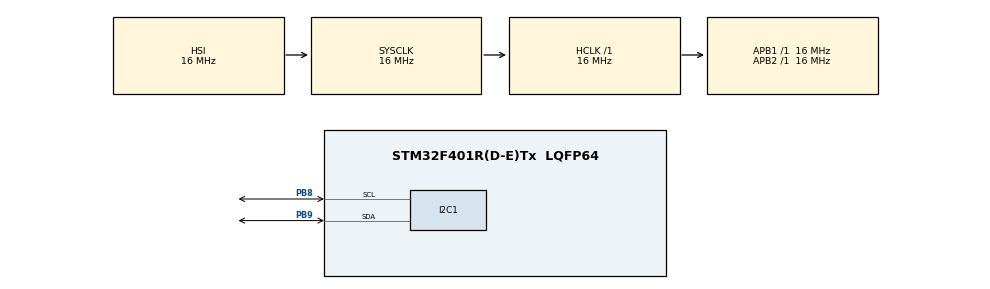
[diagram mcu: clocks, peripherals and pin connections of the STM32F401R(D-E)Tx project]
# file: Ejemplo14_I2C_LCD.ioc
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Mcu.Family=STM32F4
Mcu.Name=STM32F401R(D-E)Tx
Mcu.Package=LQFP64
NVIC.PriorityGroup=NVIC_PRIORITYGROUP_4
PA13.Mode=Serial_Wire
PA13.Signal=SYS_JTMS-SWDIO
PA14.Mode=Serial_Wire
PA14.Signal=SYS_JTCK-SWCLK
PB8.Mode=I2C
PB8.Signal=I2C1_SCL
PB9.Mode=I2C
PB9.Signal=I2C1_SDA
ProjectManager.HeapSize=0x200
ProjectManager.StackSize=0x400
ProjectManager.TargetToolchain=STM32CubeIDE
RCC.AHBFreq_Value=16000000
RCC.APB1Freq_Value=16000000
RCC.APB2Freq_Value=16000000
RCC.CortexFreq_Value=16000000
RCC.HSE_VALUE=25000000
RCC.HSI_VALUE=16000000
RCC.LSE_VALUE=32768
RCC.SYSCLKFreq_VALUE=16000000
RCC.VCOOutputFreq_Value=192000000
board=custom

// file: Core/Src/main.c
/* USER CODE BEGIN Header */
/**
  ******************************************************************************
  * @file           : main.c
  * @brief          : Main program body
  ******************************************************************************
  * @attention
  *
  * Copyright (c) 2023 STMicroelectronics.
  * All rights reserved.
  *
  * This software is licensed under terms that can be found in the LICENSE file
  * in the root directory of this software component.
  * If no LICENSE file comes with this software, it is provided AS-IS.
  *
  ******************************************************************************
  */
/* USER CODE END Header */
#include "main.h"
#include "i2c.h"
#include "gpio.h"

/* USER CODE BEGIN Includes */

#include "LCD.h"
/* USER CODE END Includes */

void SystemClock_Config(void);

int main(void)
{

  /* MCU Configuration--------------------------------------------------------*/

  /* Reset of all peripherals, Initializes the Flash interface and the Systick. */
  HAL_Init();

  /* Configure the system clock */
  SystemClock_Config();

  /* Initialize all configured peripherals */
  MX_GPIO_Init();
  MX_I2C1_Init();
  /* USER CODE BEGIN 2 */
LCD_STM32_INIT();
/*LCD_STM32_SET_CURSOR(0, fila1);
LCD_STM32_PRINT_CHAR('G');
LCD_STM32_PRINT_CHAR('O');
LCD_STM32_PRINT_CHAR('D');
LCD_STM32_PRINT_CHAR('O');
LCD_STM32_SET_CURSOR(0, fila2);
LCD_STM32_PRINT_CHAR('S');
LCD_STM32_PRINT_CHAR('T');
LCD_STM32_PRINT_CHAR('M');
LCD_STM32_PRINT_CHAR('3');
LCD_STM32_PRINT_CHAR('2');*/

LCD_STM32_SET_CURSOR(0, fila1);
LCD_STM32_PRINT_STRING("LCD CON I2C");
uint8_t count  = 0;
char str_count[15];
  /* USER CODE END 2 */

  /* Infinite loop */
  /* USER CODE BEGIN WHILE */
  while (1)
  {
	  for (count = 0; count < 256; ++count) {
		  LCD_STM32_SET_CURSOR(0, fila2);
		  sprintf(str_count,"C:%03u",count);
		  LCD_STM32_PRINT_STRING(str_count);
		  HAL_Delay(300);
	  }
    /* USER CODE END WHILE */

  }
}

void SystemClock_Config(void)
{
  RCC_OscInitTypeDef RCC_OscInitStruct = {0};
  RCC_ClkInitTypeDef RCC_ClkInitStruct = {0};

  /** Configure the main internal regulator output voltage
  */
  __HAL_RCC_PWR_CLK_ENABLE();
  __HAL_PWR_VOLTAGESCALING_CONFIG(PWR_REGULATOR_VOLTAGE_SCALE2);

  /** Initializes the RCC Oscillators according to the specified parameters
  * in the RCC_OscInitTypeDef structure.
  */
  RCC_OscInitStruct.OscillatorType = RCC_OSCILLATORTYPE_HSI;
  RCC_OscInitStruct.HSIState = RCC_HSI_ON;
  RCC_OscInitStruct.HSICalibrationValue = RCC_HSICALIBRATION_DEFAULT;
  RCC_OscInitStruct.PLL.PLLState = RCC_PLL_NONE;
  if (HAL_RCC_OscConfig(&RCC_OscInitStruct) != HAL_OK)
  {
    Error_Handler();
  }

  /** Initializes the CPU, AHB and APB buses clocks
  */
  RCC_ClkInitStruct.ClockType = RCC_CLOCKTYPE_HCLK|RCC_CLOCKTYPE_SYSCLK
                              |RCC_CLOCKTYPE_PCLK1|RCC_CLOCKTYPE_PCLK2;
  RCC_ClkInitStruct.SYSCLKSource = RCC_SYSCLKSOURCE_HSI;
  RCC_ClkInitStruct.AHBCLKDivider = RCC_SYSCLK_DIV1;
  RCC_ClkInitStruct.APB1CLKDivider = RCC_HCLK_DIV1;
  RCC_ClkInitStruct.APB2CLKDivider = RCC_HCLK_DIV1;

  if (HAL_RCC_ClockConfig(&RCC_ClkInitStruct, FLASH_LATENCY_0) != HAL_OK)
  {
    Error_Handler();
  }
}

void Error_Handler(void)
{
  __disable_irq();
  while (1)
  {
  }
}
